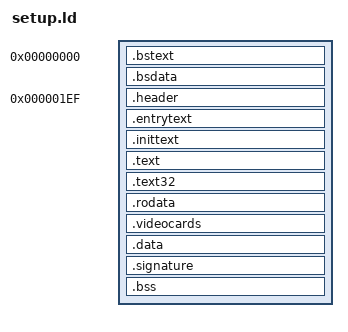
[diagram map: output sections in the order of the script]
FASTVC-BENCH-CORPUS:linux-main-100k-v1-e0bd41dc-8e12-4f1b-978d-a3645ae59da0
/*
 * setup.ld
 *
 * Linker script for the i386 setup code
 */
OUTPUT_FORMAT("elf32-i386")
OUTPUT_ARCH(i386)
ENTRY(_start)

SECTIONS
{
	. = 0;
	.bstext		: { *(.bstext) }
	.bsdata		: { *(.bsdata) }

	. = 495;
	.header		: { *(.header) }
	.entrytext	: { *(.entrytext) }
	.inittext	: { *(.inittext) }
/* bench 12714.1.0 c7eadda960cf */
/* bench 12714.1.1 d227cf9b316a */
/* bench 12714.1.2 9295040c128b */
/* bench 12714.1.3 320ea0557be7 */
/* bench 12714.1.4 b5ad444d8fc2 */
/* bench 12714.1.5 c1bf84abf3eb */
/* bench 12714.1.6 a614066989e5 */
/* bench 12714.1.7 1230b328c76f */
	.text		: { *(.text .text.*) }
	.text32		: { *(.text32) }

	. = ALIGN(16);
	.rodata		: { *(.rodata*) }

	.videocards	: {
		video_cards = .;
		*(.videocards)
		video_cards_end = .;
	}

	. = ALIGN(16);
	.data		: { *(.data*) }

	.signature	: {
		setup_sig = .;
		LONG(0x5a5aaa55)
	}


	. = ALIGN(16);
	.bss		:
	{
		__bss_start = .;
		*(.bss)
		__bss_end = .;
	}
	. = ALIGN(16);
	_end = .;

	/DISCARD/	: {
		*(.note*)
	}

	/*
	 * The ASSERT() sink to . is intentional, for binutils 2.14 compatibility:
	 */
	. = ASSERT(_end <= 0x8000, "Setup too big!");
	. = ASSERT(hdr == 0x1f1, "The setup header has the wrong offset!");
	/* Necessary for the very-old-loader check to work... */
	. = ASSERT(__end_init <= 5*512, "init sections too big!");

}
